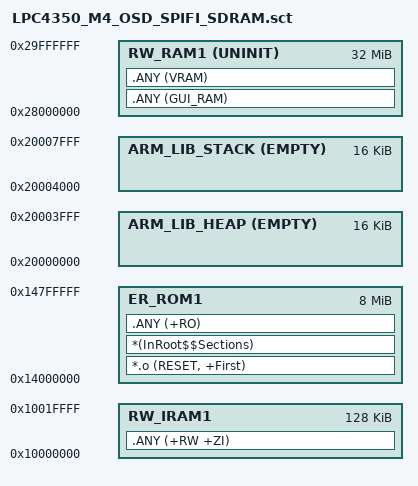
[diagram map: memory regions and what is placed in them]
; *************************************************************
; *** Scatter-Loading Description File generated by uVision ***
; *************************************************************

LR_ROM1 0x14000000 0x00800000  {    ; load region size_region
  ER_ROM1 0x14000000 0x00800000  {  ; load address = execution address
   *.o (RESET, +First)
   *(InRoot$$Sections)
   .ANY (+RO)
  }
  
  RW_IRAM1 0x10000000 0x00020000  {
   .ANY (+RW +ZI)
  }
  
  ARM_LIB_HEAP 0x20000000 EMPTY 0x4000 {
  }
  ARM_LIB_STACK 0x20008000 EMPTY -0x4000{
  }
    
  RW_RAM1 0x28000000 UNINIT 0x02000000 {
   .ANY (GUI_RAM)
   .ANY (VRAM)
  }
}

